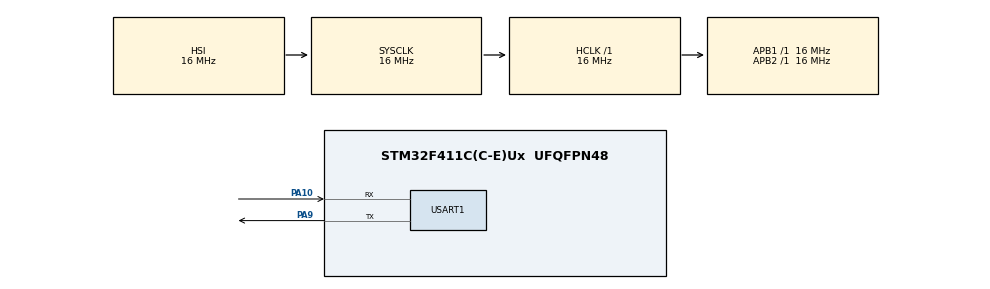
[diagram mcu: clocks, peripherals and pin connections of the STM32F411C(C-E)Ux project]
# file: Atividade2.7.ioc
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FREERTOS.Mutexes01=uartMutex,Dynamic,NULL,Available
FREERTOS.Tasks01=TaskSensor,24,128,TaskSensor_fun,Default,NULL,Dynamic,NULL,NULL;TaskControle,24,128,TaskControle_fun,Default,NULL,Dynamic,NULL,NULL
FREERTOS.configUSE_NEWLIB_REENTRANT=1
Mcu.Family=STM32F4
Mcu.Name=STM32F411C(C-E)Ux
Mcu.Package=UFQFPN48
NVIC.PriorityGroup=NVIC_PRIORITYGROUP_4
NVIC.TIM1_UP_TIM10_IRQn=true\:15\:0\:false\:false\:true\:false\:false\:true\:true
NVIC.TimeBase=TIM1_UP_TIM10_IRQn
NVIC.TimeBaseIP=TIM1
PA10.Mode=Asynchronous
PA10.Signal=USART1_RX
PA9.Mode=Asynchronous
PA9.Signal=USART1_TX
ProjectManager.HeapSize=0x200
ProjectManager.StackSize=0x400
ProjectManager.TargetToolchain=STM32CubeIDE
RCC.AHBFreq_Value=16000000
RCC.APB1Freq_Value=16000000
RCC.APB2Freq_Value=16000000
RCC.CortexFreq_Value=16000000
RCC.HSE_VALUE=25000000
RCC.HSI_VALUE=16000000
RCC.LSE_VALUE=32768
RCC.SYSCLKFreq_VALUE=16000000
RCC.VCOOutputFreq_Value=192000000
USART1.VirtualMode=VM_ASYNC
VP_FREERTOS_VS_CMSIS_V2.Mode=CMSIS_V2
VP_SYS_VS_tim1.Mode=TIM1
board=custom

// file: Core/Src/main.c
/* USER CODE BEGIN Header */
/**
  ******************************************************************************
  * @file           : main.c
  * @brief          : Main program body
  ******************************************************************************
  * @attention
  *
  * Copyright (c) 2026 STMicroelectronics.
  * All rights reserved.
  *
  * This software is licensed under terms that can be found in the LICENSE file
  * in the root directory of this software component.
  * If no LICENSE file comes with this software, it is provided AS-IS.
  *
  ******************************************************************************
  */
/* USER CODE END Header */
#include "main.h"
#include "cmsis_os.h"
#include "usart.h"
#include "gpio.h"

void SystemClock_Config(void);
void MX_FREERTOS_Init(void);

int main(void)
{

  /* MCU Configuration--------------------------------------------------------*/

  /* Reset of all peripherals, Initializes the Flash interface and the Systick. */
  HAL_Init();

  /* Configure the system clock */
  SystemClock_Config();

  /* Initialize all configured peripherals */
  MX_GPIO_Init();
  MX_USART1_UART_Init();

  /* Init scheduler */
  osKernelInitialize();  /* Call init function for freertos objects (in cmsis_os2.c) */
  MX_FREERTOS_Init();

  /* Start scheduler */
  osKernelStart();

  /* We should never get here as control is now taken by the scheduler */

  /* Infinite loop */
  while (1)
  {

  }
}

void SystemClock_Config(void)
{
  RCC_OscInitTypeDef RCC_OscInitStruct = {0};
  RCC_ClkInitTypeDef RCC_ClkInitStruct = {0};

  /** Configure the main internal regulator output voltage
  */
  __HAL_RCC_PWR_CLK_ENABLE();
  __HAL_PWR_VOLTAGESCALING_CONFIG(PWR_REGULATOR_VOLTAGE_SCALE1);

  /** Initializes the RCC Oscillators according to the specified parameters
  * in the RCC_OscInitTypeDef structure.
  */
  RCC_OscInitStruct.OscillatorType = RCC_OSCILLATORTYPE_HSI;
  RCC_OscInitStruct.HSIState = RCC_HSI_ON;
  RCC_OscInitStruct.HSICalibrationValue = RCC_HSICALIBRATION_DEFAULT;
  RCC_OscInitStruct.PLL.PLLState = RCC_PLL_NONE;
  if (HAL_RCC_OscConfig(&RCC_OscInitStruct) != HAL_OK)
  {
    Error_Handler();
  }

  /** Initializes the CPU, AHB and APB buses clocks
  */
  RCC_ClkInitStruct.ClockType = RCC_CLOCKTYPE_HCLK|RCC_CLOCKTYPE_SYSCLK
                              |RCC_CLOCKTYPE_PCLK1|RCC_CLOCKTYPE_PCLK2;
  RCC_ClkInitStruct.SYSCLKSource = RCC_SYSCLKSOURCE_HSI;
  RCC_ClkInitStruct.AHBCLKDivider = RCC_SYSCLK_DIV1;
  RCC_ClkInitStruct.APB1CLKDivider = RCC_HCLK_DIV1;
  RCC_ClkInitStruct.APB2CLKDivider = RCC_HCLK_DIV1;

  if (HAL_RCC_ClockConfig(&RCC_ClkInitStruct, FLASH_LATENCY_0) != HAL_OK)
  {
    Error_Handler();
  }
}

void HAL_TIM_PeriodElapsedCallback(TIM_HandleTypeDef *htim)
{
  if (htim->Instance == TIM1)
  {
    HAL_IncTick();
  }
}

void Error_Handler(void)
{
  __disable_irq();
  while (1)
  {
  }
}

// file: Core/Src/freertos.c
/* USER CODE BEGIN Header */
/**
  ******************************************************************************
  * File Name          : freertos.c
  * Description        : Code for freertos applications
  ******************************************************************************
  * @attention
  *
  * Copyright (c) 2026 STMicroelectronics.
  * All rights reserved.
  *
  * This software is licensed under terms that can be found in the LICENSE file
  * in the root directory of this software component.
  * If no LICENSE file comes with this software, it is provided AS-IS.
  *
  ******************************************************************************
  */
/* USER CODE END Header */

#include "FreeRTOS.h"
#include "task.h"
#include "main.h"
#include "cmsis_os.h"

/* USER CODE BEGIN Includes */
#include "usart.h"
#include <stdio.h>

/* USER CODE END Includes */

/* Definitions for TaskSensor */
osThreadId_t TaskSensorHandle;
const osThreadAttr_t TaskSensor_attributes = {
  .name = "TaskSensor",
  .stack_size = 128 * 4,
  .priority = (osPriority_t) osPriorityNormal,
};
/* Definitions for TaskControle */
osThreadId_t TaskControleHandle;
const osThreadAttr_t TaskControle_attributes = {
  .name = "TaskControle",
  .stack_size = 128 * 4,
  .priority = (osPriority_t) osPriorityNormal,
};
/* Definitions for uartMutex */
osMutexId_t uartMutexHandle;
const osMutexAttr_t uartMutex_attributes = {
  .name = "uartMutex"
};

void TaskSensor_fun(void *argument);
void TaskControle_fun(void *argument);

void MX_FREERTOS_Init(void); /* (MISRA C 2004 rule 8.1) */

void MX_FREERTOS_Init(void) {
  /* Create the mutex(es) */
  /* creation of uartMutex */
  uartMutexHandle = osMutexNew(&uartMutex_attributes);

  /* Create the thread(s) */
  /* creation of TaskSensor */
  TaskSensorHandle = osThreadNew(TaskSensor_fun, NULL, &TaskSensor_attributes);

  /* creation of TaskControle */
  TaskControleHandle = osThreadNew(TaskControle_fun, NULL, &TaskControle_attributes);

}

void TaskSensor_fun(void *argument)
{
  /* USER CODE BEGIN TaskSensor_fun */
  /* Infinite loop */
  int cicloSensor = 0;

  for(;;)
  {
	cicloSensor++;

	osMutexAcquire(uartMutexHandle, osWaitForever);

	char msg[80];
	int tamanho = snprintf(msg, sizeof(msg), "[Ciclo %d] SENSOR pegou a UART e vai demorar...\r\n", cicloSensor);
	HAL_UART_Transmit(&huart1, (uint8_t*)msg, (uint16_t)tamanho, HAL_MAX_DELAY);

	osDelay(500);

	osMutexRelease(uartMutexHandle);

	osDelay(1000);
  }
  /* USER CODE END TaskSensor_fun */
}

void TaskControle_fun(void *argument)
{
  /* USER CODE BEGIN TaskControle_fun */
  /* Infinite loop */
  int atividadesAlternativas = 0;

  for(;;)
  {
	if (osMutexAcquire(uartMutexHandle, 0) == osOK)
	{
	  char msg[100];
	  int tamanho = snprintf(msg, sizeof(msg),
		  "CONTROLE conseguiu a UART! (Fez %d outras atividades enquanto esperava)\r\n",
		  atividadesAlternativas);

	  HAL_UART_Transmit(&huart1, (uint8_t*)msg, (uint16_t)tamanho, HAL_MAX_DELAY);

	  atividadesAlternativas = 0;

	  osMutexRelease(uartMutexHandle);
	}
	else
	{
	  atividadesAlternativas++;

	}

	osDelay(100);
  }
  /* USER CODE END TaskControle_fun */
}
